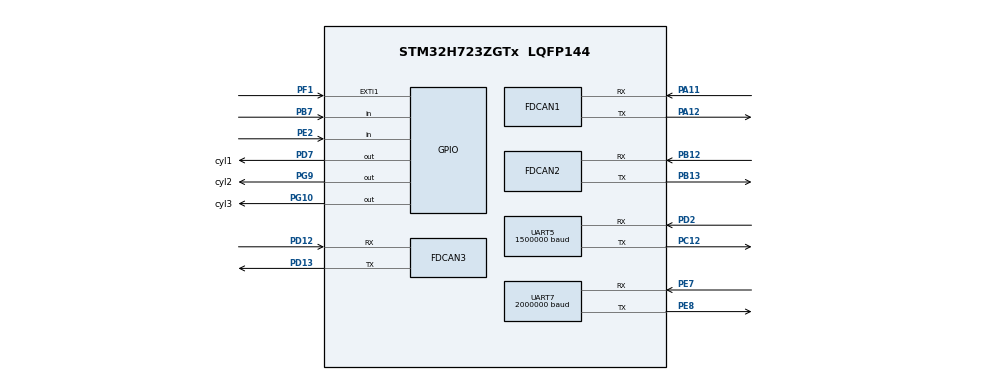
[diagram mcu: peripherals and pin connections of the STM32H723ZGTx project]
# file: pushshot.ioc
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CORTEX_M7.AccessPermission_Spec=MPU_REGION_FULL_ACCESS
CORTEX_M7.BaseAddress_Spec=0x24000000
CORTEX_M7.CPU_DCache=Enabled
CORTEX_M7.CPU_ICache=Enabled
CORTEX_M7.DisableExec_Spec=MPU_INSTRUCTION_ACCESS_ENABLE
CORTEX_M7.IsCacheable_Spec=MPU_ACCESS_CACHEABLE
CORTEX_M7.IsShareable_Spec=MPU_ACCESS_SHAREABLE
CORTEX_M7.MPU_Control=MPU_HFNMI_PRIVDEF
CORTEX_M7.Size_Spec=MPU_REGION_SIZE_64MB
CORTEX_M7.SubRegionDisable_Spec=0
CORTEX_M7.default_mode_Activation=1
Dma.Request0=UART5_TX
Dma.Request1=UART7_TX
Dma.UART5_TX.0.Direction=DMA_MEMORY_TO_PERIPH
Dma.UART5_TX.0.EventEnable=DISABLE
Dma.UART5_TX.0.FIFOMode=DMA_FIFOMODE_DISABLE
Dma.UART5_TX.0.Instance=DMA1_Stream1
Dma.UART5_TX.0.MemDataAlignment=DMA_MDATAALIGN_BYTE
Dma.UART5_TX.0.MemInc=DMA_MINC_ENABLE
Dma.UART5_TX.0.Mode=DMA_NORMAL
Dma.UART5_TX.0.PeriphDataAlignment=DMA_PDATAALIGN_BYTE
Dma.UART5_TX.0.PeriphInc=DMA_PINC_DISABLE
Dma.UART5_TX.0.Polarity=HAL_DMAMUX_REQ_GEN_RISING
Dma.UART5_TX.0.Priority=DMA_PRIORITY_MEDIUM
Dma.UART5_TX.0.RequestNumber=1
Dma.UART5_TX.0.SignalID=NONE
Dma.UART5_TX.0.SyncEnable=DISABLE
Dma.UART5_TX.0.SyncPolarity=HAL_DMAMUX_SYNC_NO_EVENT
Dma.UART5_TX.0.SyncRequestNumber=1
Dma.UART5_TX.0.SyncSignalID=NONE
Dma.UART7_TX.1.Direction=DMA_MEMORY_TO_PERIPH
Dma.UART7_TX.1.EventEnable=DISABLE
Dma.UART7_TX.1.FIFOMode=DMA_FIFOMODE_DISABLE
Dma.UART7_TX.1.Instance=DMA1_Stream0
Dma.UART7_TX.1.MemDataAlignment=DMA_MDATAALIGN_BYTE
Dma.UART7_TX.1.MemInc=DMA_MINC_ENABLE
Dma.UART7_TX.1.Mode=DMA_NORMAL
Dma.UART7_TX.1.PeriphDataAlignment=DMA_PDATAALIGN_BYTE
Dma.UART7_TX.1.PeriphInc=DMA_PINC_DISABLE
Dma.UART7_TX.1.Polarity=HAL_DMAMUX_REQ_GEN_RISING
Dma.UART7_TX.1.Priority=DMA_PRIORITY_LOW
Dma.UART7_TX.1.RequestNumber=1
Dma.UART7_TX.1.SignalID=NONE
Dma.UART7_TX.1.SyncEnable=DISABLE
Dma.UART7_TX.1.SyncPolarity=HAL_DMAMUX_SYNC_NO_EVENT
Dma.UART7_TX.1.SyncRequestNumber=1
Dma.UART7_TX.1.SyncSignalID=NONE
FDCAN1.CalculateBaudRateNominal=999999
FDCAN1.CalculateTimeBitNominal=1000
FDCAN1.CalculateTimeQuantumNominal=8.333333333333334
FDCAN1.DataPrescaler=1
FDCAN1.DataSyncJumpWidth=9
FDCAN1.DataTimeSeg1=11
FDCAN1.DataTimeSeg2=12
FDCAN1.ExtFiltersNbr=1
FDCAN1.FrameFormat=FDCAN_FRAME_FD_BRS
FDCAN1.NominalPrescaler=1
FDCAN1.NominalSyncJumpWidth=24
FDCAN1.NominalTimeSeg1=89
FDCAN1.NominalTimeSeg2=30
FDCAN1.RxFifo0ElmtSize=FDCAN_DATA_BYTES_32
FDCAN1.RxFifo0ElmtsNbr=8
FDCAN1.StdFiltersNbr=1
FDCAN1.TxElmtSize=FDCAN_DATA_BYTES_32
FDCAN1.TxFifoQueueElmtsNbr=8
FDCAN2.CalculateBaudRateNominal=999999
FDCAN2.CalculateTimeBitNominal=1000
FDCAN2.CalculateTimeQuantumNominal=8.333333333333334
FDCAN2.DataSyncJumpWidth=9
FDCAN2.DataTimeSeg1=11
FDCAN2.DataTimeSeg2=12
FDCAN2.ExtFiltersNbr=1
FDCAN2.FrameFormat=FDCAN_FRAME_FD_BRS
FDCAN2.MessageRAMOffset=512
FDCAN2.NominalPrescaler=1
FDCAN2.NominalSyncJumpWidth=24
FDCAN2.NominalTimeSeg1=89
FDCAN2.NominalTimeSeg2=30
FDCAN2.RxFifo0ElmtSize=FDCAN_DATA_BYTES_8
FDCAN2.RxFifo0ElmtsNbr=8
FDCAN2.StdFiltersNbr=1
FDCAN2.TxElmtSize=FDCAN_DATA_BYTES_8
FDCAN2.TxFifoQueueElmtsNbr=8
FDCAN3.CalculateBaudRateNominal=999999
FDCAN3.CalculateTimeBitNominal=1000
FDCAN3.CalculateTimeQuantumNominal=8.333333333333334
FDCAN3.DataPrescaler=2
FDCAN3.DataSyncJumpWidth=4
FDCAN3.DataTimeSeg1=23
FDCAN3.DataTimeSeg2=6
FDCAN3.ExtFiltersNbr=0
FDCAN3.FrameFormat=FDCAN_FRAME_FD_BRS
FDCAN3.MessageRAMOffset=1024
FDCAN3.NominalPrescaler=1
FDCAN3.NominalSyncJumpWidth=24
FDCAN3.NominalTimeSeg1=89
FDCAN3.NominalTimeSeg2=30
FDCAN3.RxFifo0ElmtSize=FDCAN_DATA_BYTES_64
FDCAN3.RxFifo0ElmtsNbr=8
FDCAN3.StdFiltersNbr=5
FDCAN3.TxElmtSize=FDCAN_DATA_BYTES_12
FDCAN3.TxFifoQueueElmtsNbr=8
Mcu.Family=STM32H7
Mcu.Name=STM32H723ZGTx
Mcu.Package=LQFP144
NVIC.EXTI1_IRQn=true\:1\:0\:true\:false\:false\:true\:false\:true
NVIC.FDCAN1_IT0_IRQn=true\:1\:0\:true\:false\:false\:true\:false\:true
NVIC.FDCAN2_IT0_IRQn=true\:1\:0\:true\:false\:false\:true\:false\:true
NVIC.FDCAN3_IT0_IRQn=true\:1\:0\:true\:false\:false\:true\:false\:true
NVIC.PriorityGroup=NVIC_PRIORITYGROUP_4
NVIC.TIM6_DAC_IRQn=true\:0\:0\:false\:false\:false\:true\:false\:true
NVIC.UART5_IRQn=true\:1\:0\:true\:false\:false\:true\:false\:true
PA11.GPIO_Speed=GPIO_SPEED_FREQ_VERY_HIGH
PA11.Mode=FDCAN_Activate
PA11.Signal=FDCAN1_RX
PA12.GPIO_Speed=GPIO_SPEED_FREQ_VERY_HIGH
PA12.Mode=FDCAN_Activate
PA12.Signal=FDCAN1_TX
PA13(JTMS/SWDIO).Mode=Serial_Wire
PA13(JTMS/SWDIO).Signal=DEBUG_JTMS-SWDIO
PA14(JTCK/SWCLK).Mode=Serial_Wire
PA14(JTCK/SWCLK).Signal=DEBUG_JTCK-SWCLK
PB12.GPIO_Speed=GPIO_SPEED_FREQ_VERY_HIGH
PB12.Mode=FDCAN_Activate
PB12.Signal=FDCAN2_RX
PB13.GPIO_Speed=GPIO_SPEED_FREQ_VERY_HIGH
PB13.Mode=FDCAN_Activate
PB13.Signal=FDCAN2_TX
PB7.Signal=GPIO_Input
PC12.GPIO_Speed=GPIO_SPEED_FREQ_VERY_HIGH
PC12.Mode=Asynchronous
PC12.Signal=UART5_TX
PD12.GPIO_Speed=GPIO_SPEED_FREQ_VERY_HIGH
PD12.Mode=FDCAN_Activate
PD12.Signal=FDCAN3_RX
PD13.GPIO_Speed=GPIO_SPEED_FREQ_VERY_HIGH
PD13.Mode=FDCAN_Activate
PD13.Signal=FDCAN3_TX
PD2.GPIO_Speed=GPIO_SPEED_FREQ_VERY_HIGH
PD2.Mode=Asynchronous
PD2.Signal=UART5_RX
PD7.GPIO_Label=cyl1
PD7.GPIO_Speed=GPIO_SPEED_FREQ_VERY_HIGH
PD7.Signal=GPIO_Output
PE2.Signal=GPIO_Input
PE7.GPIO_Speed=GPIO_SPEED_FREQ_VERY_HIGH
PE7.Mode=Asynchronous
PE7.Signal=UART7_RX
PE8.GPIO_Speed=GPIO_SPEED_FREQ_VERY_HIGH
PE8.Mode=Asynchronous
PE8.Signal=UART7_TX
PF1.Signal=GPXTI1
PG10.GPIO_Label=cyl3
PG10.GPIO_Speed=GPIO_SPEED_FREQ_VERY_HIGH
PG10.Signal=GPIO_Output
PG9.GPIO_Label=cyl2
PG9.GPIO_Speed=GPIO_SPEED_FREQ_VERY_HIGH
PG9.Signal=GPIO_Output
PH0-OSC_IN.Mode=HSE-External-Oscillator
PH0-OSC_IN.Signal=RCC_OSC_IN
PH1-OSC_OUT.Mode=HSE-External-Oscillator
PH1-OSC_OUT.Signal=RCC_OSC_OUT
ProjectManager.HeapSize=0x400
ProjectManager.StackSize=0x400
ProjectManager.TargetToolchain=MDK-ARM V5.32
RCC.ADCFreq_Value=240000000
RCC.APB1Freq_Value=137500000
RCC.APB2Freq_Value=137500000
RCC.APB3Freq_Value=137500000
RCC.APB4Freq_Value=137500000
RCC.CortexFreq_Value=550000000
RCC.D1PPRE=RCC_APB3_DIV2
RCC.D2PPRE1=RCC_APB1_DIV2
RCC.D2PPRE2=RCC_APB2_DIV2
RCC.D3PPRE=RCC_APB4_DIV2
RCC.DIVM1=5
RCC.DIVM2=5
RCC.DIVM3=5
RCC.DIVN1=110
RCC.DIVN2=48
RCC.DIVN3=48
RCC.DIVP1=1
RCC.DIVP2=1
RCC.DIVP3=1
RCC.DIVQ1=1
RCC.DIVQ3=1
RCC.DIVR1=1
RCC.FDCANCLockSelection=RCC_FDCANCLKSOURCE_PLL2
RCC.HCLKFreq_Value=275000000
RCC.HPRE=RCC_HCLK_DIV2
RCC.I2C123CLockSelection=RCC_I2C1235CLKSOURCE_PLL3
RCC.PLL2FRACN=0
RCC.PLL3FRACN=0
RCC.PLLFRACN=0
RCC.PLLSourceVirtual=RCC_PLLSOURCE_HSE
RCC.SPI123CLockSelection=RCC_SPI123CLKSOURCE_PLL2
RCC.SYSCLKFreq_VALUE=550000000
RCC.SYSCLKSource=RCC_SYSCLKSOURCE_PLLCLK
RCC.Spi45ClockSelection=RCC_SPI45CLKSOURCE_PLL2
RCC.USART16CLockSelection=RCC_USART16910CLKSOURCE_PLL2
RCC.USART234578CLockSelection=RCC_USART234578CLKSOURCE_PLL2
RCC.USBFreq_Value=550000000
TIM6.AutoReloadPreload=TIM_AUTORELOAD_PRELOAD_ENABLE
TIM6.Period=55000 - 1
TIM6.Prescaler=5 - 1
TIM7.AutoReloadPreload=TIM_AUTORELOAD_PRELOAD_ENABLE
TIM7.Period=62500 - 1
TIM7.Prescaler=4320 - 1
UART5.BaudRate=1500000
UART5.Mode=MODE_TX_RX
UART7.BaudRate=2000000
UART7.Mode=MODE_TX
VP_MEMORYMAP_VS_MEMORYMAP.Mode=CurAppReg
VP_TIM6_VS_ClockSourceINT.Mode=Enable_Timer
VP_TIM7_VS_ClockSourceINT.Mode=Enable_Timer
board=custom

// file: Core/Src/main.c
/* USER CODE BEGIN Header */
/**
 ******************************************************************************
 * @file           : main.c
 * @brief          : Main program body
 ******************************************************************************
 * @attention
 *
 * Copyright (c) 2025 STMicroelectronics.
 * All rights reserved.
 *
 * This software is licensed under terms that can be found in the LICENSE file
 * in the root directory of this software component.
 * If no LICENSE file comes with this software, it is provided AS-IS.
 *
 ******************************************************************************
 */
/* USER CODE END Header */
#include "main.h"

/* USER CODE BEGIN Includes */
#include "usr.h"
/* USER CODE END Includes */

FDCAN_HandleTypeDef hfdcan1;
FDCAN_HandleTypeDef hfdcan2;
FDCAN_HandleTypeDef hfdcan3;

TIM_HandleTypeDef htim6;
TIM_HandleTypeDef htim7;

UART_HandleTypeDef huart5;
UART_HandleTypeDef huart7;
DMA_HandleTypeDef hdma_uart5_tx;
DMA_HandleTypeDef hdma_uart7_tx;

void SystemClock_Config(void);
void PeriphCommonClock_Config(void);
static void MPU_Config(void);
static void MX_GPIO_Init(void);
static void MX_DMA_Init(void);
static void MX_FDCAN1_Init(void);
static void MX_FDCAN2_Init(void);
static void MX_FDCAN3_Init(void);
static void MX_TIM7_Init(void);
static void MX_UART5_Init(void);
static void MX_UART7_Init(void);
static void MX_TIM6_Init(void);

int main(void)
{

  /* MPU Configuration--------------------------------------------------------*/
  MPU_Config();

  /* Enable the CPU Cache */

  /* Enable I-Cache---------------------------------------------------------*/
  SCB_EnableICache();

  /* Enable D-Cache---------------------------------------------------------*/
  SCB_EnableDCache();

  /* MCU Configuration--------------------------------------------------------*/

  /* Reset of all peripherals, Initializes the Flash interface and the Systick. */
  HAL_Init();

  /* Configure the system clock */
  SystemClock_Config();

  /* Configure the peripherals common clocks */
  PeriphCommonClock_Config();

  /* Initialize all configured peripherals */
  MX_GPIO_Init();
  MX_DMA_Init();
  MX_FDCAN1_Init();
  MX_FDCAN2_Init();
  MX_FDCAN3_Init();
  MX_TIM7_Init();
  MX_UART5_Init();
  MX_UART7_Init();
  MX_TIM6_Init();
  /* USER CODE BEGIN 2 */
  PeriphInit();
  /* USER CODE END 2 */

  /* Infinite loop */
  /* USER CODE BEGIN WHILE */
  Scheduler();
  /* USER CODE END WHILE */

}

void SystemClock_Config(void)
{
  RCC_OscInitTypeDef RCC_OscInitStruct = {0};
  RCC_ClkInitTypeDef RCC_ClkInitStruct = {0};

  /** Supply configuration update enable
   */
  HAL_PWREx_ConfigSupply(PWR_LDO_SUPPLY);

  /** Configure the main internal regulator output voltage
   */
  __HAL_PWR_VOLTAGESCALING_CONFIG(PWR_REGULATOR_VOLTAGE_SCALE0);

  while (!__HAL_PWR_GET_FLAG(PWR_FLAG_VOSRDY))
  {
  }

  /** Initializes the RCC Oscillators according to the specified parameters
   * in the RCC_OscInitTypeDef structure.
   */
  RCC_OscInitStruct.OscillatorType = RCC_OSCILLATORTYPE_HSE;
  RCC_OscInitStruct.HSEState = RCC_HSE_ON;
  RCC_OscInitStruct.PLL.PLLState = RCC_PLL_ON;
  RCC_OscInitStruct.PLL.PLLSource = RCC_PLLSOURCE_HSE;
  RCC_OscInitStruct.PLL.PLLM = 5;
  RCC_OscInitStruct.PLL.PLLN = 110;
  RCC_OscInitStruct.PLL.PLLP = 1;
  RCC_OscInitStruct.PLL.PLLQ = 1;
  RCC_OscInitStruct.PLL.PLLR = 1;
  RCC_OscInitStruct.PLL.PLLRGE = RCC_PLL1VCIRANGE_2;
  RCC_OscInitStruct.PLL.PLLVCOSEL = RCC_PLL1VCOWIDE;
  RCC_OscInitStruct.PLL.PLLFRACN = 0;
  if (HAL_RCC_OscConfig(&RCC_OscInitStruct) != HAL_OK)
  {
    Error_Handler();
  }

  /** Initializes the CPU, AHB and APB buses clocks
   */
  RCC_ClkInitStruct.ClockType = RCC_CLOCKTYPE_HCLK | RCC_CLOCKTYPE_SYSCLK | RCC_CLOCKTYPE_PCLK1 | RCC_CLOCKTYPE_PCLK2 | RCC_CLOCKTYPE_D3PCLK1 | RCC_CLOCKTYPE_D1PCLK1;
  RCC_ClkInitStruct.SYSCLKSource = RCC_SYSCLKSOURCE_PLLCLK;
  RCC_ClkInitStruct.SYSCLKDivider = RCC_SYSCLK_DIV1;
  RCC_ClkInitStruct.AHBCLKDivider = RCC_HCLK_DIV2;
  RCC_ClkInitStruct.APB3CLKDivider = RCC_APB3_DIV2;
  RCC_ClkInitStruct.APB1CLKDivider = RCC_APB1_DIV2;
  RCC_ClkInitStruct.APB2CLKDivider = RCC_APB2_DIV2;
  RCC_ClkInitStruct.APB4CLKDivider = RCC_APB4_DIV2;

  if (HAL_RCC_ClockConfig(&RCC_ClkInitStruct, FLASH_LATENCY_3) != HAL_OK)
  {
    Error_Handler();
  }
}

void PeriphCommonClock_Config(void)
{
  RCC_PeriphCLKInitTypeDef PeriphClkInitStruct = {0};

  /** Initializes the peripherals clock
   */
  PeriphClkInitStruct.PeriphClockSelection = RCC_PERIPHCLK_UART5 | RCC_PERIPHCLK_FDCAN | RCC_PERIPHCLK_UART7;
  PeriphClkInitStruct.PLL2.PLL2M = 5;
  PeriphClkInitStruct.PLL2.PLL2N = 48;
  PeriphClkInitStruct.PLL2.PLL2P = 1;
  PeriphClkInitStruct.PLL2.PLL2Q = 2;
  PeriphClkInitStruct.PLL2.PLL2R = 2;
  PeriphClkInitStruct.PLL2.PLL2RGE = RCC_PLL2VCIRANGE_2;
  PeriphClkInitStruct.PLL2.PLL2VCOSEL = RCC_PLL2VCOWIDE;
  PeriphClkInitStruct.PLL2.PLL2FRACN = 0;
  PeriphClkInitStruct.FdcanClockSelection = RCC_FDCANCLKSOURCE_PLL2;
  PeriphClkInitStruct.Usart234578ClockSelection = RCC_USART234578CLKSOURCE_PLL2;
  if (HAL_RCCEx_PeriphCLKConfig(&PeriphClkInitStruct) != HAL_OK)
  {
    Error_Handler();
  }
}

static void MX_FDCAN1_Init(void)
{

  hfdcan1.Instance = FDCAN1;
  hfdcan1.Init.FrameFormat = FDCAN_FRAME_FD_BRS;
  hfdcan1.Init.Mode = FDCAN_MODE_NORMAL;
  hfdcan1.Init.AutoRetransmission = DISABLE;
  hfdcan1.Init.TransmitPause = DISABLE;
  hfdcan1.Init.ProtocolException = DISABLE;
  hfdcan1.Init.NominalPrescaler = 1;
  hfdcan1.Init.NominalSyncJumpWidth = 24;
  hfdcan1.Init.NominalTimeSeg1 = 89;
  hfdcan1.Init.NominalTimeSeg2 = 30;
  hfdcan1.Init.DataPrescaler = 1;
  hfdcan1.Init.DataSyncJumpWidth = 9;
  hfdcan1.Init.DataTimeSeg1 = 11;
  hfdcan1.Init.DataTimeSeg2 = 12;
  hfdcan1.Init.MessageRAMOffset = 0;
  hfdcan1.Init.StdFiltersNbr = 1;
  hfdcan1.Init.ExtFiltersNbr = 1;
  hfdcan1.Init.RxFifo0ElmtsNbr = 8;
  hfdcan1.Init.RxFifo0ElmtSize = FDCAN_DATA_BYTES_32;
  hfdcan1.Init.RxFifo1ElmtsNbr = 0;
  hfdcan1.Init.RxFifo1ElmtSize = FDCAN_DATA_BYTES_8;
  hfdcan1.Init.RxBuffersNbr = 0;
  hfdcan1.Init.RxBufferSize = FDCAN_DATA_BYTES_8;
  hfdcan1.Init.TxEventsNbr = 0;
  hfdcan1.Init.TxBuffersNbr = 0;
  hfdcan1.Init.TxFifoQueueElmtsNbr = 8;
  hfdcan1.Init.TxFifoQueueMode = FDCAN_TX_FIFO_OPERATION;
  hfdcan1.Init.TxElmtSize = FDCAN_DATA_BYTES_32;
  if (HAL_FDCAN_Init(&hfdcan1) != HAL_OK)
  {
    Error_Handler();
  }
}

static void MX_FDCAN2_Init(void)
{

  hfdcan2.Instance = FDCAN2;
  hfdcan2.Init.FrameFormat = FDCAN_FRAME_FD_BRS;
  hfdcan2.Init.Mode = FDCAN_MODE_NORMAL;
  hfdcan2.Init.AutoRetransmission = DISABLE;
  hfdcan2.Init.TransmitPause = DISABLE;
  hfdcan2.Init.ProtocolException = DISABLE;
  hfdcan2.Init.NominalPrescaler = 1;
  hfdcan2.Init.NominalSyncJumpWidth = 24;
  hfdcan2.Init.NominalTimeSeg1 = 89;
  hfdcan2.Init.NominalTimeSeg2 = 30;
  hfdcan2.Init.DataPrescaler = 1;
  hfdcan2.Init.DataSyncJumpWidth = 9;
  hfdcan2.Init.DataTimeSeg1 = 11;
  hfdcan2.Init.DataTimeSeg2 = 12;
  hfdcan2.Init.MessageRAMOffset = 512;
  hfdcan2.Init.StdFiltersNbr = 1;
  hfdcan2.Init.ExtFiltersNbr = 1;
  hfdcan2.Init.RxFifo0ElmtsNbr = 8;
  hfdcan2.Init.RxFifo0ElmtSize = FDCAN_DATA_BYTES_8;
  hfdcan2.Init.RxFifo1ElmtsNbr = 0;
  hfdcan2.Init.RxFifo1ElmtSize = FDCAN_DATA_BYTES_8;
  hfdcan2.Init.RxBuffersNbr = 0;
  hfdcan2.Init.RxBufferSize = FDCAN_DATA_BYTES_8;
  hfdcan2.Init.TxEventsNbr = 0;
  hfdcan2.Init.TxBuffersNbr = 0;
  hfdcan2.Init.TxFifoQueueElmtsNbr = 8;
  hfdcan2.Init.TxFifoQueueMode = FDCAN_TX_FIFO_OPERATION;
  hfdcan2.Init.TxElmtSize = FDCAN_DATA_BYTES_8;
  if (HAL_FDCAN_Init(&hfdcan2) != HAL_OK)
  {
    Error_Handler();
  }
}

static void MX_FDCAN3_Init(void)
{

  hfdcan3.Instance = FDCAN3;
  hfdcan3.Init.FrameFormat = FDCAN_FRAME_FD_BRS;
  hfdcan3.Init.Mode = FDCAN_MODE_NORMAL;
  hfdcan3.Init.AutoRetransmission = DISABLE;
  hfdcan3.Init.TransmitPause = DISABLE;
  hfdcan3.Init.ProtocolException = DISABLE;
  hfdcan3.Init.NominalPrescaler = 1;
  hfdcan3.Init.NominalSyncJumpWidth = 24;
  hfdcan3.Init.NominalTimeSeg1 = 89;
  hfdcan3.Init.NominalTimeSeg2 = 30;
  hfdcan3.Init.DataPrescaler = 2;
  hfdcan3.Init.DataSyncJumpWidth = 4;
  hfdcan3.Init.DataTimeSeg1 = 23;
  hfdcan3.Init.DataTimeSeg2 = 6;
  hfdcan3.Init.MessageRAMOffset = 1024;
  hfdcan3.Init.StdFiltersNbr = 5;
  hfdcan3.Init.ExtFiltersNbr = 0;
  hfdcan3.Init.RxFifo0ElmtsNbr = 8;
  hfdcan3.Init.RxFifo0ElmtSize = FDCAN_DATA_BYTES_64;
  hfdcan3.Init.RxFifo1ElmtsNbr = 0;
  hfdcan3.Init.RxFifo1ElmtSize = FDCAN_DATA_BYTES_8;
  hfdcan3.Init.RxBuffersNbr = 0;
  hfdcan3.Init.RxBufferSize = FDCAN_DATA_BYTES_8;
  hfdcan3.Init.TxEventsNbr = 0;
  hfdcan3.Init.TxBuffersNbr = 0;
  hfdcan3.Init.TxFifoQueueElmtsNbr = 8;
  hfdcan3.Init.TxFifoQueueMode = FDCAN_TX_FIFO_OPERATION;
  hfdcan3.Init.TxElmtSize = FDCAN_DATA_BYTES_12;
  if (HAL_FDCAN_Init(&hfdcan3) != HAL_OK)
  {
    Error_Handler();
  }
}

static void MX_TIM6_Init(void)
{

  TIM_MasterConfigTypeDef sMasterConfig = {0};

  htim6.Instance = TIM6;
  htim6.Init.Prescaler = 5 - 1;
  htim6.Init.CounterMode = TIM_COUNTERMODE_UP;
  htim6.Init.Period = 55000 - 1;
  htim6.Init.AutoReloadPreload = TIM_AUTORELOAD_PRELOAD_ENABLE;
  if (HAL_TIM_Base_Init(&htim6) != HAL_OK)
  {
    Error_Handler();
  }
  sMasterConfig.MasterOutputTrigger = TIM_TRGO_RESET;
  sMasterConfig.MasterSlaveMode = TIM_MASTERSLAVEMODE_DISABLE;
  if (HAL_TIMEx_MasterConfigSynchronization(&htim6, &sMasterConfig) != HAL_OK)
  {
    Error_Handler();
  }
}

static void MX_TIM7_Init(void)
{

  TIM_MasterConfigTypeDef sMasterConfig = {0};

  htim7.Instance = TIM7;
  htim7.Init.Prescaler = 4320 - 1;
  htim7.Init.CounterMode = TIM_COUNTERMODE_UP;
  htim7.Init.Period = 62500 - 1;
  htim7.Init.AutoReloadPreload = TIM_AUTORELOAD_PRELOAD_ENABLE;
  if (HAL_TIM_Base_Init(&htim7) != HAL_OK)
  {
    Error_Handler();
  }
  sMasterConfig.MasterOutputTrigger = TIM_TRGO_RESET;
  sMasterConfig.MasterSlaveMode = TIM_MASTERSLAVEMODE_DISABLE;
  if (HAL_TIMEx_MasterConfigSynchronization(&htim7, &sMasterConfig) != HAL_OK)
  {
    Error_Handler();
  }
}

static void MX_UART5_Init(void)
{

  huart5.Instance = UART5;
  huart5.Init.BaudRate = 1500000;
  huart5.Init.WordLength = UART_WORDLENGTH_8B;
  huart5.Init.StopBits = UART_STOPBITS_1;
  huart5.Init.Parity = UART_PARITY_NONE;
  huart5.Init.Mode = UART_MODE_TX_RX;
  huart5.Init.HwFlowCtl = UART_HWCONTROL_NONE;
  huart5.Init.OverSampling = UART_OVERSAMPLING_16;
  huart5.Init.OneBitSampling = UART_ONE_BIT_SAMPLE_DISABLE;
  huart5.Init.ClockPrescaler = UART_PRESCALER_DIV1;
  huart5.AdvancedInit.AdvFeatureInit = UART_ADVFEATURE_NO_INIT;
  if (HAL_UART_Init(&huart5) != HAL_OK)
  {
    Error_Handler();
  }
  if (HAL_UARTEx_SetTxFifoThreshold(&huart5, UART_TXFIFO_THRESHOLD_1_8) != HAL_OK)
  {
    Error_Handler();
  }
  if (HAL_UARTEx_SetRxFifoThreshold(&huart5, UART_RXFIFO_THRESHOLD_1_8) != HAL_OK)
  {
    Error_Handler();
  }
  if (HAL_UARTEx_DisableFifoMode(&huart5) != HAL_OK)
  {
    Error_Handler();
  }
}

static void MX_UART7_Init(void)
{

  huart7.Instance = UART7;
  huart7.Init.BaudRate = 2000000;
  huart7.Init.WordLength = UART_WORDLENGTH_8B;
  huart7.Init.StopBits = UART_STOPBITS_1;
  huart7.Init.Parity = UART_PARITY_NONE;
  huart7.Init.Mode = UART_MODE_TX;
  huart7.Init.HwFlowCtl = UART_HWCONTROL_NONE;
  huart7.Init.OverSampling = UART_OVERSAMPLING_16;
  huart7.Init.OneBitSampling = UART_ONE_BIT_SAMPLE_DISABLE;
  huart7.Init.ClockPrescaler = UART_PRESCALER_DIV1;
  huart7.AdvancedInit.AdvFeatureInit = UART_ADVFEATURE_NO_INIT;
  if (HAL_UART_Init(&huart7) != HAL_OK)
  {
    Error_Handler();
  }
  if (HAL_UARTEx_SetTxFifoThreshold(&huart7, UART_TXFIFO_THRESHOLD_1_8) != HAL_OK)
  {
    Error_Handler();
  }
  if (HAL_UARTEx_SetRxFifoThreshold(&huart7, UART_RXFIFO_THRESHOLD_1_8) != HAL_OK)
  {
    Error_Handler();
  }
  if (HAL_UARTEx_DisableFifoMode(&huart7) != HAL_OK)
  {
    Error_Handler();
  }
}

static void MX_DMA_Init(void)
{

  /* DMA controller clock enable */
  __HAL_RCC_DMA1_CLK_ENABLE();
}

static void MX_GPIO_Init(void)
{
  GPIO_InitTypeDef GPIO_InitStruct = {0};

  /* GPIO Ports Clock Enable */
  __HAL_RCC_GPIOE_CLK_ENABLE();
  __HAL_RCC_GPIOC_CLK_ENABLE();
  __HAL_RCC_GPIOF_CLK_ENABLE();
  __HAL_RCC_GPIOH_CLK_ENABLE();
  __HAL_RCC_GPIOA_CLK_ENABLE();
  __HAL_RCC_GPIOB_CLK_ENABLE();
  __HAL_RCC_GPIOG_CLK_ENABLE();
  __HAL_RCC_GPIOD_CLK_ENABLE();

  /*Configure GPIO pin Output Level */
  HAL_GPIO_WritePin(cyl1_GPIO_Port, cyl1_Pin, GPIO_PIN_RESET);

  /*Configure GPIO pin Output Level */
  HAL_GPIO_WritePin(GPIOG, cyl2_Pin | cyl3_Pin, GPIO_PIN_RESET);

  /*Configure GPIO pin : PE2 */
  GPIO_InitStruct.Pin = GPIO_PIN_2;
  GPIO_InitStruct.Mode = GPIO_MODE_INPUT;
  GPIO_InitStruct.Pull = GPIO_NOPULL;
  HAL_GPIO_Init(GPIOE, &GPIO_InitStruct);

  /*Configure GPIO pins : PE3 PE4 PE5 PE6
                           PE9 PE10 PE11 PE12
                           PE13 PE14 PE15 PE0
                           PE1 */
  GPIO_InitStruct.Pin = GPIO_PIN_3 | GPIO_PIN_4 | GPIO_PIN_5 | GPIO_PIN_6 | GPIO_PIN_9 | GPIO_PIN_10 | GPIO_PIN_11 | GPIO_PIN_12 | GPIO_PIN_13 | GPIO_PIN_14 | GPIO_PIN_15 | GPIO_PIN_0 | GPIO_PIN_1;
  GPIO_InitStruct.Mode = GPIO_MODE_ANALOG;
  GPIO_InitStruct.Pull = GPIO_NOPULL;
  HAL_GPIO_Init(GPIOE, &GPIO_InitStruct);

  /*Configure GPIO pins : PC13 PC14 PC15 PC0
                           PC1 PC2 PC3 PC4
                           PC5 PC6 PC7 PC8
                           PC9 PC10 PC11 */
  GPIO_InitStruct.Pin = GPIO_PIN_13 | GPIO_PIN_14 | GPIO_PIN_15 | GPIO_PIN_0 | GPIO_PIN_1 | GPIO_PIN_2 | GPIO_PIN_3 | GPIO_PIN_4 | GPIO_PIN_5 | GPIO_PIN_6 | GPIO_PIN_7 | GPIO_PIN_8 | GPIO_PIN_9 | GPIO_PIN_10 | GPIO_PIN_11;
  GPIO_InitStruct.Mode = GPIO_MODE_ANALOG;
  GPIO_InitStruct.Pull = GPIO_NOPULL;
  HAL_GPIO_Init(GPIOC, &GPIO_InitStruct);

  /*Configure GPIO pins : PF0 PF2 PF3 PF4
                           PF5 PF6 PF7 PF8
                           PF9 PF10 PF11 PF12
                           PF13 PF14 PF15 */
  GPIO_InitStruct.Pin = GPIO_PIN_0 | GPIO_PIN_2 | GPIO_PIN_3 | GPIO_PIN_4 | GPIO_PIN_5 | GPIO_PIN_6 | GPIO_PIN_7 | GPIO_PIN_8 | GPIO_PIN_9 | GPIO_PIN_10 | GPIO_PIN_11 | GPIO_PIN_12 | GPIO_PIN_13 | GPIO_PIN_14 | GPIO_PIN_15;
  GPIO_InitStruct.Mode = GPIO_MODE_ANALOG;
  GPIO_InitStruct.Pull = GPIO_NOPULL;
  HAL_GPIO_Init(GPIOF, &GPIO_InitStruct);

  /*Configure GPIO pin : PF1 */
  GPIO_InitStruct.Pin = GPIO_PIN_1;
  GPIO_InitStruct.Mode = GPIO_MODE_IT_RISING;
  GPIO_InitStruct.Pull = GPIO_NOPULL;
  HAL_GPIO_Init(GPIOF, &GPIO_InitStruct);

  /*Configure GPIO pins : PA0 PA1 PA2 PA3
                           PA4 PA5 PA6 PA7
                           PA8 PA9 PA10 PA15 */
  GPIO_InitStruct.Pin = GPIO_PIN_0 | GPIO_PIN_1 | GPIO_PIN_2 | GPIO_PIN_3 | GPIO_PIN_4 | GPIO_PIN_5 | GPIO_PIN_6 | GPIO_PIN_7 | GPIO_PIN_8 | GPIO_PIN_9 | GPIO_PIN_10 | GPIO_PIN_15;
  GPIO_InitStruct.Mode = GPIO_MODE_ANALOG;
  GPIO_InitStruct.Pull = GPIO_NOPULL;
  HAL_GPIO_Init(GPIOA, &GPIO_InitStruct);

  /*Configure GPIO pins : PB0 PB1 PB2 PB10
                           PB11 PB14 PB15 PB3
                           PB4 PB5 PB6 PB8
                           PB9 */
  GPIO_InitStruct.Pin = GPIO_PIN_0 | GPIO_PIN_1 | GPIO_PIN_2 | GPIO_PIN_10 | GPIO_PIN_11 | GPIO_PIN_14 | GPIO_PIN_15 | GPIO_PIN_3 | GPIO_PIN_4 | GPIO_PIN_5 | GPIO_PIN_6 | GPIO_PIN_8 | GPIO_PIN_9;
  GPIO_InitStruct.Mode = GPIO_MODE_ANALOG;
  GPIO_InitStruct.Pull = GPIO_NOPULL;
  HAL_GPIO_Init(GPIOB, &GPIO_InitStruct);

  /*Configure GPIO pins : PG0 PG1 PG2 PG3
                           PG4 PG5 PG6 PG7
                           PG8 PG11 PG12 PG13
                           PG14 PG15 */
  GPIO_InitStruct.Pin = GPIO_PIN_0 | GPIO_PIN_1 | GPIO_PIN_2 | GPIO_PIN_3 | GPIO_PIN_4 | GPIO_PIN_5 | GPIO_PIN_6 | GPIO_PIN_7 | GPIO_PIN_8 | GPIO_PIN_11 | GPIO_PIN_12 | GPIO_PIN_13 | GPIO_PIN_14 | GPIO_PIN_15;
  GPIO_InitStruct.Mode = GPIO_MODE_ANALOG;
  GPIO_InitStruct.Pull = GPIO_NOPULL;
  HAL_GPIO_Init(GPIOG, &GPIO_InitStruct);

  /*Configure GPIO pins : PD8 PD9 PD10 PD11
                           PD14 PD15 PD0 PD1
                           PD3 PD4 PD5 PD6 */
  GPIO_InitStruct.Pin = GPIO_PIN_8 | GPIO_PIN_9 | GPIO_PIN_10 | GPIO_PIN_11 | GPIO_PIN_14 | GPIO_PIN_15 | GPIO_PIN_0 | GPIO_PIN_1 | GPIO_PIN_3 | GPIO_PIN_4 | GPIO_PIN_5 | GPIO_PIN_6;
  GPIO_InitStruct.Mode = GPIO_MODE_ANALOG;
  GPIO_InitStruct.Pull = GPIO_NOPULL;
  HAL_GPIO_Init(GPIOD, &GPIO_InitStruct);

  /*Configure GPIO pin : cyl1_Pin */
  GPIO_InitStruct.Pin = cyl1_Pin;
  GPIO_InitStruct.Mode = GPIO_MODE_OUTPUT_PP;
  GPIO_InitStruct.Pull = GPIO_NOPULL;
  GPIO_InitStruct.Speed = GPIO_SPEED_FREQ_VERY_HIGH;
  HAL_GPIO_Init(cyl1_GPIO_Port, &GPIO_InitStruct);

  /*Configure GPIO pins : cyl2_Pin cyl3_Pin */
  GPIO_InitStruct.Pin = cyl2_Pin | cyl3_Pin;
  GPIO_InitStruct.Mode = GPIO_MODE_OUTPUT_PP;
  GPIO_InitStruct.Pull = GPIO_NOPULL;
  GPIO_InitStruct.Speed = GPIO_SPEED_FREQ_VERY_HIGH;
  HAL_GPIO_Init(GPIOG, &GPIO_InitStruct);

  /*Configure GPIO pin : PB7 */
  GPIO_InitStruct.Pin = GPIO_PIN_7;
  GPIO_InitStruct.Mode = GPIO_MODE_INPUT;
  GPIO_InitStruct.Pull = GPIO_NOPULL;
  HAL_GPIO_Init(GPIOB, &GPIO_InitStruct);

  /* EXTI interrupt init*/
  HAL_NVIC_SetPriority(EXTI1_IRQn, 1, 0);
  HAL_NVIC_EnableIRQ(EXTI1_IRQn);

}

/* MPU Configuration */

void MPU_Config(void)
{
  MPU_Region_InitTypeDef MPU_InitStruct = {0};

  /* Disables the MPU */
  HAL_MPU_Disable();

  /** Initializes and configures the Region and the memory to be protected
   */
  MPU_InitStruct.Enable = MPU_REGION_ENABLE;
  MPU_InitStruct.Number = MPU_REGION_NUMBER0;
  MPU_InitStruct.BaseAddress = 0x24000000;
  MPU_InitStruct.Size = MPU_REGION_SIZE_64MB;
  MPU_InitStruct.SubRegionDisable = 0;
  MPU_InitStruct.TypeExtField = MPU_TEX_LEVEL0;
  MPU_InitStruct.AccessPermission = MPU_REGION_FULL_ACCESS;
  MPU_InitStruct.DisableExec = MPU_INSTRUCTION_ACCESS_ENABLE;
  MPU_InitStruct.IsShareable = MPU_ACCESS_SHAREABLE;
  MPU_InitStruct.IsCacheable = MPU_ACCESS_CACHEABLE;
  MPU_InitStruct.IsBufferable = MPU_ACCESS_NOT_BUFFERABLE;

  HAL_MPU_ConfigRegion(&MPU_InitStruct);
  /* Enables the MPU */
  HAL_MPU_Enable(MPU_HFNMI_PRIVDEF);
}

void Error_Handler(void)
{
  __disable_irq();
  while (1)
  {
  }
}
